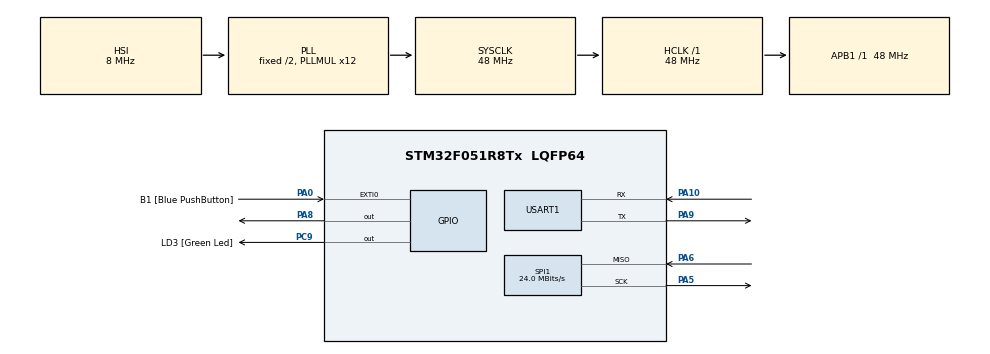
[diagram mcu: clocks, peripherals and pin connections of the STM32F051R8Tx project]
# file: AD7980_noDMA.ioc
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Mcu.Family=STM32F0
Mcu.Name=STM32F051R8Tx
Mcu.Package=LQFP64
PA0.GPIO_Label=B1 [Blue PushButton]
PA0.GPIO_ModeDefaultEXTI=GPIO_MODE_EVT_RISING
PA0.Signal=GPXTI0
PA10.Mode=Asynchronous
PA10.Signal=USART1_RX
PA13.GPIO_Label=SWDIO
PA13.Mode=Serial_Wire
PA13.Signal=SYS_SWDIO
PA14.Mode=Serial_Wire
PA14.Signal=SYS_SWCLK
PA5.Mode=RX_Only_Simplex_Unidirect_Master
PA5.Signal=SPI1_SCK
PA6.Mode=RX_Only_Simplex_Unidirect_Master
PA6.Signal=SPI1_MISO
PA8.Signal=GPIO_Output
PA9.Mode=Asynchronous
PA9.Signal=USART1_TX
PC9.GPIO_Label=LD3 [Green Led]
PC9.Signal=GPIO_Output
ProjectManager.HeapSize=0x200
ProjectManager.StackSize=0x400
ProjectManager.TargetToolchain=STM32CubeIDE
RCC.AHBFreq_Value=48000000
RCC.APB1Freq_Value=48000000
RCC.APB1TimFreq_Value=48000000
RCC.HCLKFreq_Value=48000000
RCC.PLLMUL=RCC_PLL_MUL12
RCC.SYSCLKFreq_VALUE=48000000
RCC.SYSCLKSource=RCC_SYSCLKSOURCE_PLLCLK
SPI1.BaudRatePrescaler=SPI_BAUDRATEPRESCALER_2
SPI1.CalculateBaudRate=24.0 MBits/s
SPI1.Direction=SPI_DIRECTION_2LINES_RXONLY
SPI1.Mode=SPI_MODE_MASTER
SPI1.VirtualType=VM_MASTER
USART1.VirtualMode-Asynchronous=VM_ASYNC
board=STM32F0DISCOVERY

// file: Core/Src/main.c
/* USER CODE BEGIN Header */
/**
  ******************************************************************************
  * @file           : main.c
  * @brief          : Main program body
  ******************************************************************************
  * @attention
  *
  * Copyright (c) 2023 STMicroelectronics.
  * All rights reserved.
  *
  * This software is licensed under terms that can be found in the LICENSE file
  * in the root directory of this software component.
  * If no LICENSE file comes with this software, it is provided AS-IS.
  *
  ******************************************************************************
  */
/* USER CODE END Header */
#include "main.h"

/* USER CODE BEGIN Includes */
#include <stdio.h>
/* USER CODE END Includes */

SPI_HandleTypeDef hspi1;

UART_HandleTypeDef huart1;

void SystemClock_Config(void);
static void MX_GPIO_Init(void);
static void MX_SPI1_Init(void);
static void MX_USART1_UART_Init(void);

int main(void)
{
  /* USER CODE BEGIN 1 */
	//uart set up to print to console
	HAL_StatusTypeDef rxStatus;
	char uartBuffer[30];
	uint8_t rxBuffer[2]; //two bytes of data read by ADC SPI communication
  /* USER CODE END 1 */

  /* MCU Configuration--------------------------------------------------------*/

  /* Reset of all peripherals, Initializes the Flash interface and the Systick. */
  HAL_Init();

  /* USER CODE BEGIN Init */
  //CNV time at least 500nanoseconds
  //time between conversion 1.2nanoseconds
  /* USER CODE END Init */

  /* Configure the system clock */
  SystemClock_Config();

  /* Initialize all configured peripherals */
  MX_GPIO_Init();
  MX_SPI1_Init();
  MX_USART1_UART_Init();
  /* USER CODE BEGIN 2 */
  //need to transmit through SCK with Master to Slave?cannot find out how

  //delay for conversion time
  /* USER CODE END 2 */

  /* Infinite loop */
  /* USER CODE BEGIN WHILE */
  while (1)
  {
	//SDI tied to VIO drives chip select pin high, therefore pull down to initiate acquisition phase
	HAL_GPIO_WritePin(GPIOA, GPIO_PIN_8, GPIO_PIN_SET);
	HAL_Delay(1); //delay by 1ms to allow for conversion phase
	HAL_GPIO_WritePin(GPIOA, GPIO_PIN_8, GPIO_PIN_RESET);
	rxStatus = HAL_SPI_Receive(&hspi1, (uint8_t*)rxBuffer, 2, HAL_MAX_DELAY); //receive rxBuffer through poll
	if (rxStatus!=HAL_OK) {
		sprintf(uartBuffer, "SPI MISO ERROR\r\n");
	} else {
		//proceed transfer data into uartBuffer to transmit
		sprintf(uartBuffer, "SPI buffer data: %d\r\n", rxBuffer[1]);
	}
	HAL_UART_Transmit(&huart1, (uint8_t*)uartBuffer, 2, HAL_MAX_DELAY);
    /* USER CODE END WHILE */
    /* USER CODE BEGIN 3 */
  }
  HAL_Delay(500); //wait half second
  /* USER CODE END 3 */
}

void SystemClock_Config(void)
{
  RCC_OscInitTypeDef RCC_OscInitStruct = {0};
  RCC_ClkInitTypeDef RCC_ClkInitStruct = {0};
  RCC_PeriphCLKInitTypeDef PeriphClkInit = {0};

  /** Initializes the RCC Oscillators according to the specified parameters
  * in the RCC_OscInitTypeDef structure.
  */
  RCC_OscInitStruct.OscillatorType = RCC_OSCILLATORTYPE_HSI;
  RCC_OscInitStruct.HSIState = RCC_HSI_ON;
  RCC_OscInitStruct.HSICalibrationValue = RCC_HSICALIBRATION_DEFAULT;
  RCC_OscInitStruct.PLL.PLLState = RCC_PLL_ON;
  RCC_OscInitStruct.PLL.PLLSource = RCC_PLLSOURCE_HSI;
  RCC_OscInitStruct.PLL.PLLMUL = RCC_PLL_MUL12;
  RCC_OscInitStruct.PLL.PREDIV = RCC_PREDIV_DIV1;
  if (HAL_RCC_OscConfig(&RCC_OscInitStruct) != HAL_OK)
  {
    Error_Handler();
  }

  /** Initializes the CPU, AHB and APB buses clocks
  */
  RCC_ClkInitStruct.ClockType = RCC_CLOCKTYPE_HCLK|RCC_CLOCKTYPE_SYSCLK
                              |RCC_CLOCKTYPE_PCLK1;
  RCC_ClkInitStruct.SYSCLKSource = RCC_SYSCLKSOURCE_PLLCLK;
  RCC_ClkInitStruct.AHBCLKDivider = RCC_SYSCLK_DIV1;
  RCC_ClkInitStruct.APB1CLKDivider = RCC_HCLK_DIV1;

  if (HAL_RCC_ClockConfig(&RCC_ClkInitStruct, FLASH_LATENCY_1) != HAL_OK)
  {
    Error_Handler();
  }
  PeriphClkInit.PeriphClockSelection = RCC_PERIPHCLK_USART1;
  PeriphClkInit.Usart1ClockSelection = RCC_USART1CLKSOURCE_PCLK1;
  if (HAL_RCCEx_PeriphCLKConfig(&PeriphClkInit) != HAL_OK)
  {
    Error_Handler();
  }
}

static void MX_SPI1_Init(void)
{

  /* SPI1 parameter configuration*/
  hspi1.Instance = SPI1;
  hspi1.Init.Mode = SPI_MODE_MASTER;
  hspi1.Init.Direction = SPI_DIRECTION_2LINES_RXONLY;
  hspi1.Init.DataSize = SPI_DATASIZE_16BIT;
  hspi1.Init.CLKPolarity = SPI_POLARITY_LOW;
  hspi1.Init.CLKPhase = SPI_PHASE_1EDGE;
  hspi1.Init.NSS = SPI_NSS_SOFT;
  hspi1.Init.BaudRatePrescaler = SPI_BAUDRATEPRESCALER_64;
  hspi1.Init.FirstBit = SPI_FIRSTBIT_MSB;
  hspi1.Init.TIMode = SPI_TIMODE_DISABLE;
  hspi1.Init.CRCCalculation = SPI_CRCCALCULATION_DISABLE;
  hspi1.Init.CRCPolynomial = 7;
  hspi1.Init.CRCLength = SPI_CRC_LENGTH_DATASIZE;
  hspi1.Init.NSSPMode = SPI_NSS_PULSE_ENABLE;
  if (HAL_SPI_Init(&hspi1) != HAL_OK)
  {
    Error_Handler();
  }

}

static void MX_USART1_UART_Init(void)
{

  huart1.Instance = USART1;
  huart1.Init.BaudRate = 38400;
  huart1.Init.WordLength = UART_WORDLENGTH_8B;
  huart1.Init.StopBits = UART_STOPBITS_1;
  huart1.Init.Parity = UART_PARITY_NONE;
  huart1.Init.Mode = UART_MODE_TX_RX;
  huart1.Init.HwFlowCtl = UART_HWCONTROL_NONE;
  huart1.Init.OverSampling = UART_OVERSAMPLING_16;
  huart1.Init.OneBitSampling = UART_ONE_BIT_SAMPLE_DISABLE;
  huart1.AdvancedInit.AdvFeatureInit = UART_ADVFEATURE_NO_INIT;
  if (HAL_UART_Init(&huart1) != HAL_OK)
  {
    Error_Handler();
  }

}

static void MX_GPIO_Init(void)
{
  GPIO_InitTypeDef GPIO_InitStruct = {0};

  /* GPIO Ports Clock Enable */
  __HAL_RCC_GPIOA_CLK_ENABLE();
  __HAL_RCC_GPIOC_CLK_ENABLE();
  __HAL_RCC_GPIOB_CLK_ENABLE();

  /*Configure GPIO pin Output Level */
  HAL_GPIO_WritePin(LD3_GPIO_Port, LD3_Pin, GPIO_PIN_RESET);

  /*Configure GPIO pin Output Level */
  HAL_GPIO_WritePin(GPIOA, GPIO_PIN_8, GPIO_PIN_RESET);

  /*Configure GPIO pin : B1_Pin */
  GPIO_InitStruct.Pin = B1_Pin;
  GPIO_InitStruct.Mode = GPIO_MODE_EVT_RISING;
  GPIO_InitStruct.Pull = GPIO_NOPULL;
  HAL_GPIO_Init(B1_GPIO_Port, &GPIO_InitStruct);

  /*Configure GPIO pin : LD3_Pin */
  GPIO_InitStruct.Pin = LD3_Pin;
  GPIO_InitStruct.Mode = GPIO_MODE_OUTPUT_PP;
  GPIO_InitStruct.Pull = GPIO_NOPULL;
  GPIO_InitStruct.Speed = GPIO_SPEED_FREQ_LOW;
  HAL_GPIO_Init(LD3_GPIO_Port, &GPIO_InitStruct);

  /*Configure GPIO pin : PA8 */
  GPIO_InitStruct.Pin = GPIO_PIN_8;
  GPIO_InitStruct.Mode = GPIO_MODE_OUTPUT_PP;
  GPIO_InitStruct.Pull = GPIO_NOPULL;
  GPIO_InitStruct.Speed = GPIO_SPEED_FREQ_LOW;
  HAL_GPIO_Init(GPIOA, &GPIO_InitStruct);

}

void Error_Handler(void)
{
  __disable_irq();
  while (1)
  {
  }
}
